# SA3_SS0_SA_UL_0_MMRA register map
Vendor: Texas Instruments
Peripheral module from a debugger description file (folder am62P).
Registers are 32-bit, write-only, reset 0x0 unless marked. A register's access mark holds for its fields unless they carry their own. Offsets are as the file gives them; lines under a group give offsets from that group; [hi:lo] are bit positions; {n}, {i} and the like mark numbered series; 'fields as' and 'values as' point back to an identical list; <NAME> marks a mode.

## SA3_SS0_SA_UL_0_MMRA
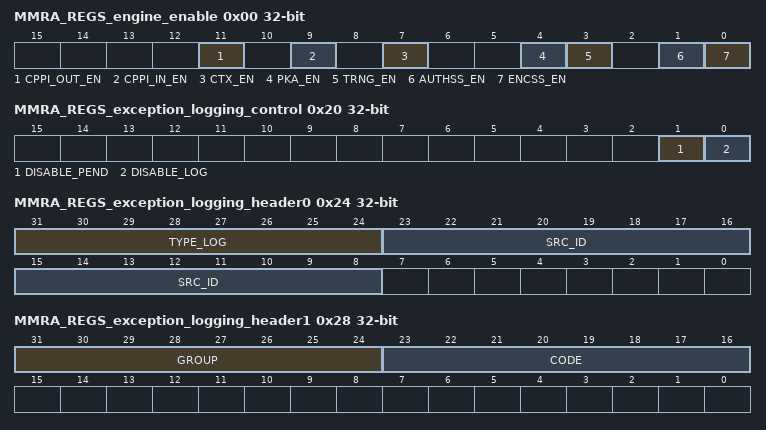
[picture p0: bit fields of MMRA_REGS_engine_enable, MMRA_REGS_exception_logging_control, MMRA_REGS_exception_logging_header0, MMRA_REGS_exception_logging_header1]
0x00 MMRA_REGS_engine_enable rw — This register controls the enable of each crypto engine
  [11] CPPI_OUT_EN — cppi out enable
  [9] CPPI_IN_EN — cppi in enable
  [7] CTX_EN — ctxcach enable
  [4] PKA_EN — pka enable
  [3] TRNG_EN — trng enable
  [1] AUTHSS_EN — authss enable
  [0] ENCSS_EN — encss enable
0x10 MMRA_REGS_scptr_promote_low_range_l rw — This register contains bit 31:0 of the SCPTR lower limit for promotion check
  [31:0] BIT_31_0 — The lower 32-bits of SCPTR lower limit
0x14 MMRA_REGS_scptr_promote_low_range_h rw — This register contains bit 47:32 of the SCPTR lower limit for promotion check
  [15:0] BIT_47_32 — The upper 16-bits of SCPTR lower limit
0x18 MMRA_REGS_scptr_promote_hi_range_l rw — This register contains bit 31:0 of the SCPTR upper limit for promotion check
  [31:0] BIT_31_0 — The lower 32-bits of SCPTR upper limit
0x1C MMRA_REGS_scptr_promote_hi_range_h rw — This register contains bit 47:32 of the SCPTR upper limit for promotion check
  [15:0] BIT_47_32 — The upper 16-bits of SCPTR upper limit
0x20 MMRA_REGS_exception_logging_control rw — The Exception Logging Control Register controls the exception logging.
  [1] DISABLE_PEND — Disables logging pending when set.
  [0] DISABLE_LOG — Disables logging when set.
0x24 MMRA_REGS_exception_logging_header0 ro — The Exception Logging Header 0 Register contains the first word of the header.
  [31:24] TYPE_LOG — Type.
  [23:8] SRC_ID — Source ID.
0x28 MMRA_REGS_exception_logging_header1 ro — The Exception Logging Header 1 Register contains the second word of the header.
  [31:24] GROUP, [23:16] CODE
0x2C MMRA_REGS_exception_logging_data0 ro — The Exception Logging Data 0 Register contains the first word of the data.
  [31:0] ADDR_L — SCPTR lower 32 bits.
0x30 MMRA_REGS_exception_logging_data1 ro — The Exception Logging Data 1 Register contains the second word of the data.
  [15:0] ADDR_H — SCPTR upper 16 bits.
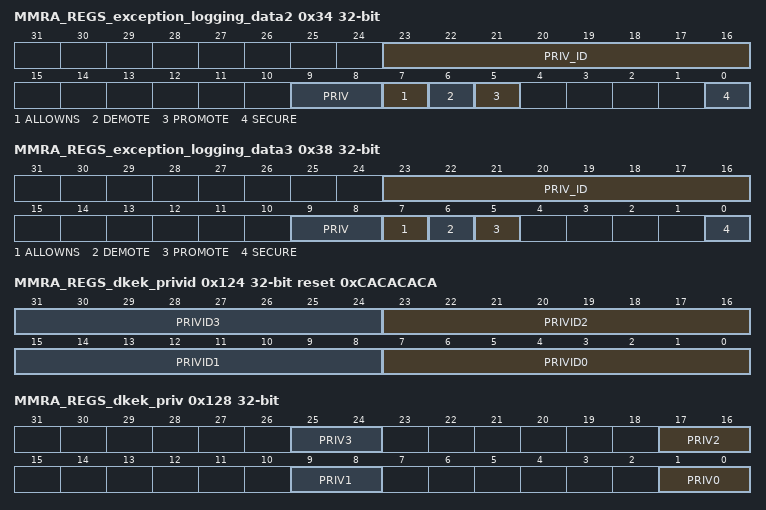
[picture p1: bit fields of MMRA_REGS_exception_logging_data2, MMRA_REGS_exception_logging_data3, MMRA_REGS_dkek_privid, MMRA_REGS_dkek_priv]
0x34 MMRA_REGS_exception_logging_data2 ro — The Exception Logging Data 2 Register contains the third word of the data.
  [23:16] PRIV_ID — Ingress Packet Priv ID attribute.
  [9:8] PRIV — Ingress Packet Priv attribute.
  [7] ALLOWNS — Ingress Packet AllowNS attribute.
  [6] DEMOTE — Ingress Packet Demote attribute.
  [5] PROMOTE — Ingress Packet Promote attribute.
  [0] SECURE — Ingress Packet Secure attribute.
0x38 MMRA_REGS_exception_logging_data3 ro — The Exception Logging Data 3 Register contains the fourth word of the data.
  [23:16] PRIV_ID — Context Priv ID.
  [9:8] PRIV — Context Priv.
  [7] ALLOWNS — Context AllowNS.
  [6] DEMOTE — Context Demote.
  [5] PROMOTE — Context Promote.
  [0] SECURE — Context Secure.
0x40 MMRA_REGS_exception_pend_set access not given — The Exception Logging Pending Set Register allows to set the pend signal.
  [0] PEND_SET — Write a 1 to set the exception pend signal. (access R/W1TS)
0x44 MMRA_REGS_exception_pend_clear access not given — The Exception Logging Pending Clear Register allows to clear the pend signal.
  [0] PEND_CLR — Write a 1 to clear the exception pend signal. (access R/W1TC)
0x50 MMRA_REGS_trng_intr_set access not given — The TRNG Interrupt Set Register allows to set trng_intr output for testing purpose.
  [0] TRNG_SET — Write a 1 to set the interrupt. (access R/W1TS)
0x54 MMRA_REGS_trng_intr_clear access not given — The TRNG Interrupt Clear Register allows to clear the trng_intr output for testing purpose.
  [0] TRNG_CLR — Write a 1 to clear the exception pend signal. (access R/W1TC)
0x60 MMRA_REGS_pka_intr_set access not given — The PKA Interrupt Set Register allows to set pka_intr output for testing purpose.
  [0] PKA_SET — Write a 1 to set the interrupt. (access R/W1TS)
0x64 MMRA_REGS_pka_intr_clear access not given — The PKA Interrupt Clear Register allows to clear the pka_intr output for testing purpose.
  [0] PKA_CLR — Write a 1 to clear the exception pend signal. (access R/W1TC)
{0x100+4i} MMRA_REGS_kek_{i} (i=0..7) — DKEK key is used as AES key only when Use_DKEK bit in the context is set to 1.
  [31:0] KEYS — bit {32i+31}:{32i} of DKEK keys
0x120 MMRA_REGS_kek_lock — This register can be written to lock and prevent further write access to kek_0 - kek_7 registers.
  [0] LOCK — The lock bit is only writable once. Once set, the kek registers cannot be reprogrammed without resetting the device
0x124 MMRA_REGS_dkek_privid reset 0xCACACACA — Only packet with privid matching any one of the programmed four privid values in this write-only register is allowed to use the encryption engine with D-KEK key. This feature is only enabled if the Use_DKEK bit in the context is set.
  [8n+7:8n] PRIVID{n} (n=0..3) — slot{n} of privid that is allowed to use D-KEK
0x128 MMRA_REGS_dkek_priv — Only packet with priv matching any one of the programmed four priv values in this write-only register will be allowed to use the encryption engine with D-KEK key. This feature is only enabled if the Use_DKEK bit in the context is set.
  [8n+1:8n] PRIV{n} (n=0..3) — slot{n} of priv that is allowed to use D-KEK
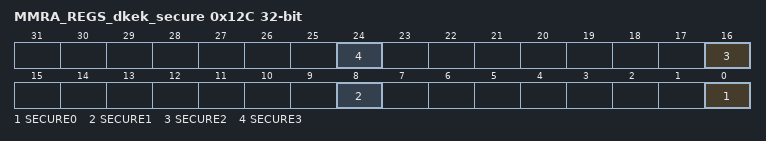
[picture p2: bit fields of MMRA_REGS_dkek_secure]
0x12C MMRA_REGS_dkek_secure — Only packet with secure matching any one of the programmed four secure values in this write-only register will be allowed to use the encryption engine with D-KEK key. This feature is only enabled if the Use_DKEK bit in the context is set.
  [8n] SECURE{n} (n=0..3) — slot{n} of secure that is allowed to use D-KEK
